AUTOSAR XML (schema 314)
package /ComponentType
  internal behavior Sa_CmMtrCurr_InternalBehavior: component=Sa_CmMtrCurr
    4 x timing event:
      CmMtrCurr_InitEvent: start-on-event=CmMtrCurr_Init, period=0
      TMT_CmMtrCurr_Per1: start-on-event=CmMtrCurr_Per1, period=0.1
      TMT_CmMtrCurr_Per2: mode-dependency=dependent-on-mode=[SystemState.Mode.DISABLE, SystemState.Mode.OFF, SystemState.Mode.WARMINIT], start-on-event=CmMtrCurr_Per2, period=0.002
      TMT_CmMtrCurr_Per3: mode-dependency=dependent-on-mode=[SystemState.Mode.DISABLE, SystemState.Mode.OFF, SystemState.Mode.WARMINIT], start-on-event=CmMtrCurr_Per3, period=0.002
    7 x operation invoked event:
      OIT_CmMtrCurr_SCom_CalGain_CmMtrCurr_SCom_CalGain: start-on-event=CmMtrCurr_SCom_CalGain, operation=CmMtrCurr_SCom.CalGain
      OIT_CmMtrCurr_SCom_CalOffset_CmMtrCurr_SCom_CalOffset: start-on-event=CmMtrCurr_SCom_CalOffset, operation=CmMtrCurr_SCom.CalOffset
      OIT_CmMtrCurr_SCom_MtrCurrOffReadStatus_CmMtrCurr_SCom_MtrCurrOffReadStatus: start-on-event=CmMtrCurr_SCom_MtrCurrOffReadStatus, operation=CmMtrCurr_SCom.MtrCurrOffReadStatus
      OIT_CmMtrCurr_SCom_ReadMtrCurrCals_CmMtrCurr_SCom_ReadMtrCurrCals: start-on-event=CmMtrCurr_SCom_ReadMtrCurrCals, operation=CmMtrCurr_SCom.ReadMtrCurrCals
      OIT_CmMtrCurr_SCom_SetMtrCurrCals_CmMtrCurr_SCom_SetMtrCurrCals: start-on-event=CmMtrCurr_SCom_SetMtrCurrCals, operation=CmMtrCurr_SCom.SetMtrCurrCals
      OIT_CmMtrCurrTempOffset_Scom_Get_CmMtrCurrTempOffset_Scom_Get: start-on-event=CmMtrCurrTempOffset_Scom_Get, operation=CmMtrCurrTempOffset_Scom.Get
      OIT_CmMtrCurrTempOffset_Scom_Set_CmMtrCurrTempOffset_Scom_Set: start-on-event=CmMtrCurrTempOffset_Scom_Set, operation=CmMtrCurrTempOffset_Scom.Set
    per instance memory CurrTempOffset: type=CurrTempOffsetType, type-definition=/DataType/CurrTempOffsetType
    per instance memory ShCurrCal: type=PhaseCurrCal_DataType, type-definition=/DataType/PhaseCurrCal_DataType
    port-api-options:
      enable-take-address=false, indirect-api=false, port=ADCMtrCurr1
      enable-take-address=false, indirect-api=false, port=ADCMtrCurr2
      enable-take-address=false, indirect-api=false, port=CmMtrCurr_SCom
      enable-take-address=false, indirect-api=false, port=CmMtrCurrTempOffset_Scom
      enable-take-address=false, indirect-api=false, port=ComOffset
      enable-take-address=false, indirect-api=false, port=CorrMtrCurrPosition
      enable-take-address=false, indirect-api=false, port=CurrentGainSvc
      enable-take-address=false, indirect-api=false, port=EOLCurrTempOffset
      enable-take-address=false, indirect-api=false, port=EOLShCurrCal
      enable-take-address=false, indirect-api=false, port=FiltCntrlTemp
      enable-take-address=false, indirect-api=false, port=MEC
      enable-take-address=false, indirect-api=false, port=MtrCurr1TempOffset
      enable-take-address=false, indirect-api=false, port=MtrCurr2TempOffset
      enable-take-address=false, indirect-api=false, port=MtrCurrAngle
      enable-take-address=false, indirect-api=false, port=MtrCurrK1
      enable-take-address=false, indirect-api=false, port=MtrCurrK2
      enable-take-address=false, indirect-api=false, port=MtrVel
      enable-take-address=false, indirect-api=false, port=NxtrDiagMgr
      enable-take-address=false, indirect-api=false, port=SrlComSvcDft
      enable-take-address=false, indirect-api=false, port=SystemState
      enable-take-address=false, indirect-api=false, port=Vecu
      enable-take-address=false, indirect-api=false, port=VehSpd
      enable-take-address=false, indirect-api=false, port=VhSpdValid
    11 x runnable:
      CmMtrCurr_Init
      CmMtrCurr_Per1
        data read access READ_FiltCntrlTemp_DegC_f32: data-element=FiltCntrlTemp.DegC_f32
        data write access WRITE_MtrCurr1TempOffset_Volt_f32: data-element=MtrCurr1TempOffset.Volt_f32
        data write access WRITE_MtrCurr2TempOffset_Volt_f32: data-element=MtrCurr2TempOffset.Volt_f32
      CmMtrCurr_Per2
        6 x data read access:
          READ_ADCMtrCurr1_Volts_f32: data-element=ADCMtrCurr1.Volts_f32
          READ_ADCMtrCurr2_Volts_f32: data-element=ADCMtrCurr2.Volts_f32
          READ_CorrMtrCurrPosition_Rev_f32: data-element=CorrMtrCurrPosition.Rev_f32
          READ_MtrCurrAngle_Rev_f32: data-element=MtrCurrAngle.Rev_f32
          READ_MtrCurrK1_Amp_f32: data-element=MtrCurrK1.Amp_f32
          READ_MtrCurrK2_Amp_f32: data-element=MtrCurrK2.Amp_f32
        sync call SC_NxtrDiagMgr_SetNTCStatus: operation=NxtrDiagMgr.SetNTCStatus, timeout=0
      CmMtrCurr_Per3
        7 x data read access:
          READ_ADCMtrCurr1_Volts_f32: data-element=ADCMtrCurr1.Volts_f32
          READ_ADCMtrCurr2_Volts_f32: data-element=ADCMtrCurr2.Volts_f32
          READ_MtrVel_MtrRadpS_f32: data-element=MtrVel.MtrRadpS_f32
          READ_SrlComSvcDft_Cnt_b32: data-element=SrlComSvcDft.Cnt_b32
          READ_Vecu_Volt_f32: data-element=Vecu.Volt_f32
          READ_VehSpd_Kph_f32: data-element=VehSpd.Kph_f32
          READ_VhSpdValid_Cnt_lgc: data-element=VhSpdValid.Cnt_lgc
        data write access WRITE_ComOffset_Cnt_u16: data-element=ComOffset.Cnt_u16
        sync call SC_EOLShCurrCal_WriteBlock: operation=EOLShCurrCal.WriteBlock, timeout=0
      CmMtrCurr_SCom_CalGain
        4 x data receive point:
          REC_MEC_Cnt_enum: data-element=MEC.Cnt_enum
          REC_MtrVel_MtrRadpS_f32: data-element=MtrVel.MtrRadpS_f32
          REC_VehSpd_Kph_f32: data-element=VehSpd.Kph_f32
          REC_VhSpdValid_Cnt_lgc: data-element=VhSpdValid.Cnt_lgc
        sync call SC_EOLShCurrCal_SetRamBlockStatus: operation=EOLShCurrCal.SetRamBlockStatus, timeout=0
        sync call SC_EOLShCurrCal_WriteBlock: operation=EOLShCurrCal.WriteBlock, timeout=0
      CmMtrCurr_SCom_CalOffset
        4 x data receive point:
          REC_MEC_Cnt_enum: data-element=MEC.Cnt_enum
          REC_MtrVel_MtrRadpS_f32: data-element=MtrVel.MtrRadpS_f32
          REC_VehSpd_Kph_f32: data-element=VehSpd.Kph_f32
          REC_VhSpdValid_Cnt_lgc: data-element=VhSpdValid.Cnt_lgc
        data send point SEND_CurrentGainSvc_Cnt_lgc: data-element=CurrentGainSvc.Cnt_lgc
      CmMtrCurr_SCom_MtrCurrOffReadStatus
      CmMtrCurr_SCom_ReadMtrCurrCals
      CmMtrCurr_SCom_SetMtrCurrCals
        sync call SC_EOLShCurrCal_WriteBlock: operation=EOLShCurrCal.WriteBlock, timeout=0
      CmMtrCurrTempOffset_Scom_Get
      CmMtrCurrTempOffset_Scom_Set
        sync call SC_EOLCurrTempOffset_WriteBlock: operation=EOLCurrTempOffset.WriteBlock, timeout=0
    service-needss:
      swc nv block needs ShCurrCalBlk: n-data-sets=0, readonly=false, reliability=LOW, resistant-to-changed-sw=false, restore-at-start=false, write-only-once=false, writing-frequency=0, writing-priority=LOW, mirror-block=ShCurrCal
      swc nv block needs CurrTempOffsetBlk: n-data-sets=0, readonly=false, reliability=LOW, resistant-to-changed-sw=false, restore-at-start=false, write-only-once=false, writing-frequency=0, writing-priority=LOW, mirror-block=CurrTempOffset
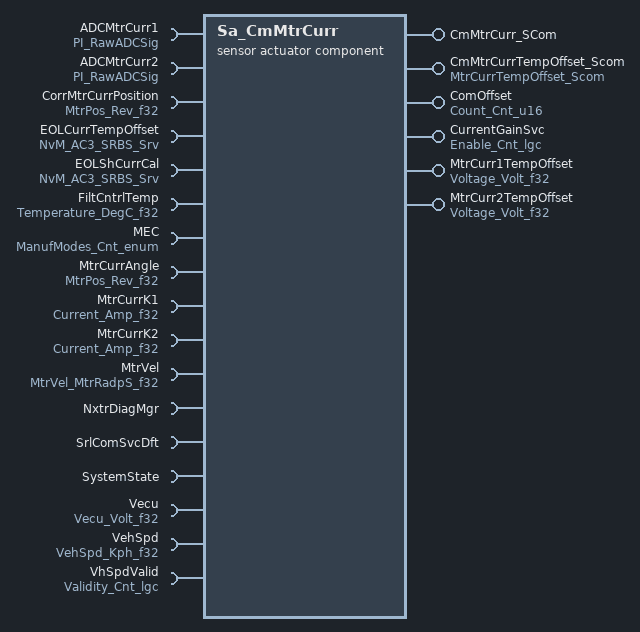
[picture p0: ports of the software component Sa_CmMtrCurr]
  sensor actuator software component type Sa_CmMtrCurr
    6 x provide port:
      CmMtrCurr_SCom: provided-interface=CmMtrCurr_SCom
        provided-com-specs:
          operation=CalGain, queue-length=1
          operation=CalOffset, queue-length=1
          operation=MtrCurrOffReadStatus, queue-length=1
          operation=ReadMtrCurrCals, queue-length=1
          operation=SetMtrCurrCals, queue-length=1
      CmMtrCurrTempOffset_Scom: provided-com-specs=[{operation=Get, queue-length=1}, {operation=Set, queue-length=1}], provided-interface=MtrCurrTempOffset_Scom
      ComOffset: unqueued-sender-com-spec{data-element=Cnt_u16, can-invalidate=false, init-value=D_ZERO_CNT_U16}, provided-interface=Count_Cnt_u16
      CurrentGainSvc: unqueued-sender-com-spec{data-element=Cnt_lgc, can-invalidate=false, init-value=D_FALSE_CNT_LGC}, provided-interface=Enable_Cnt_lgc
      MtrCurr1TempOffset: unqueued-sender-com-spec{data-element=Volt_f32, can-invalidate=false, init-value=D_ZERO_ULS_F32}, provided-interface=Voltage_Volt_f32
      MtrCurr2TempOffset: unqueued-sender-com-spec{data-element=Volt_f32, can-invalidate=false, init-value=D_ZERO_ULS_F32}, provided-interface=Voltage_Volt_f32
    17 x require port:
      ADCMtrCurr1: unqueued-receiver-com-spec{data-element=Volts_f32, init-value=D_FLOATZERO_ULS_F32}, required-interface=PI_RawADCSig
      ADCMtrCurr2: unqueued-receiver-com-spec{data-element=Volts_f32, init-value=D_FLOATZERO_ULS_F32}, required-interface=PI_RawADCSig
      CorrMtrCurrPosition: unqueued-receiver-com-spec{data-element=Rev_f32, init-value=D_ZERO_ULS_F32}, required-interface=MtrPos_Rev_f32
      EOLCurrTempOffset: required-com-specs=[EraseBlock, GetErrorStatus, InvalidateNvBlock, ReadBlock, SetRamBlockStatus, WriteBlock], required-interface=NvM_AC3_SRBS_Srv
      EOLShCurrCal: required-com-specs=[EraseBlock, GetErrorStatus, InvalidateNvBlock, ReadBlock, SetRamBlockStatus, WriteBlock], required-interface=NvM_AC3_SRBS_Srv
      FiltCntrlTemp: unqueued-receiver-com-spec{data-element=DegC_f32, init-value=D_ZERO_ULS_F32}, required-interface=Temperature_DegC_f32
      MEC: unqueued-receiver-com-spec{data-element=Cnt_enum, init-value=D_MANUFMODEINIT_CNT_ENUM}, required-interface=ManufModes_Cnt_enum
      MtrCurrAngle: unqueued-receiver-com-spec{data-element=Rev_f32, init-value=D_ZERO_ULS_F32}, required-interface=MtrPos_Rev_f32
      MtrCurrK1: unqueued-receiver-com-spec{data-element=Amp_f32, init-value=D_ZERO_ULS_F32}, required-interface=Current_Amp_f32
      MtrCurrK2: unqueued-receiver-com-spec{data-element=Amp_f32, init-value=D_ZERO_ULS_F32}, required-interface=Current_Amp_f32
      MtrVel: unqueued-receiver-com-spec{data-element=MtrRadpS_f32, init-value=D_ZERO_ULS_F32}, required-interface=MtrVel_MtrRadpS_f32
      NxtrDiagMgr: required-com-specs=[GetNTCActive, GetNTCFailed, GetNTCStatus, SetNTCStatus], required-interface=NxtrDiagMgr
      SrlComSvcDft: unqueued-receiver-com-spec{data-element=Cnt_b32, init-value=D_ZERO_CNT_U32}, required-interface=SrlComSvcDft
      SystemState: required-interface=SystemState
      Vecu: unqueued-receiver-com-spec{data-element=Volt_f32, init-value=D_VECUMIN_VOLTS_F32}, required-interface=Vecu_Volt_f32
      VehSpd: unqueued-receiver-com-spec{data-element=Kph_f32, init-value=D_ZERO_ULS_F32}, required-interface=VehSpd_Kph_f32
      VhSpdValid: unqueued-receiver-com-spec{data-element=Cnt_lgc, init-value=D_FALSE_CNT_LGC}, required-interface=Validity_Cnt_lgc
  swc implementation Sa_CmMtrCurr_Implementation: behavior=Sa_CmMtrCurr_InternalBehavior
    code-descriptors:
      code Code: type=SRC
